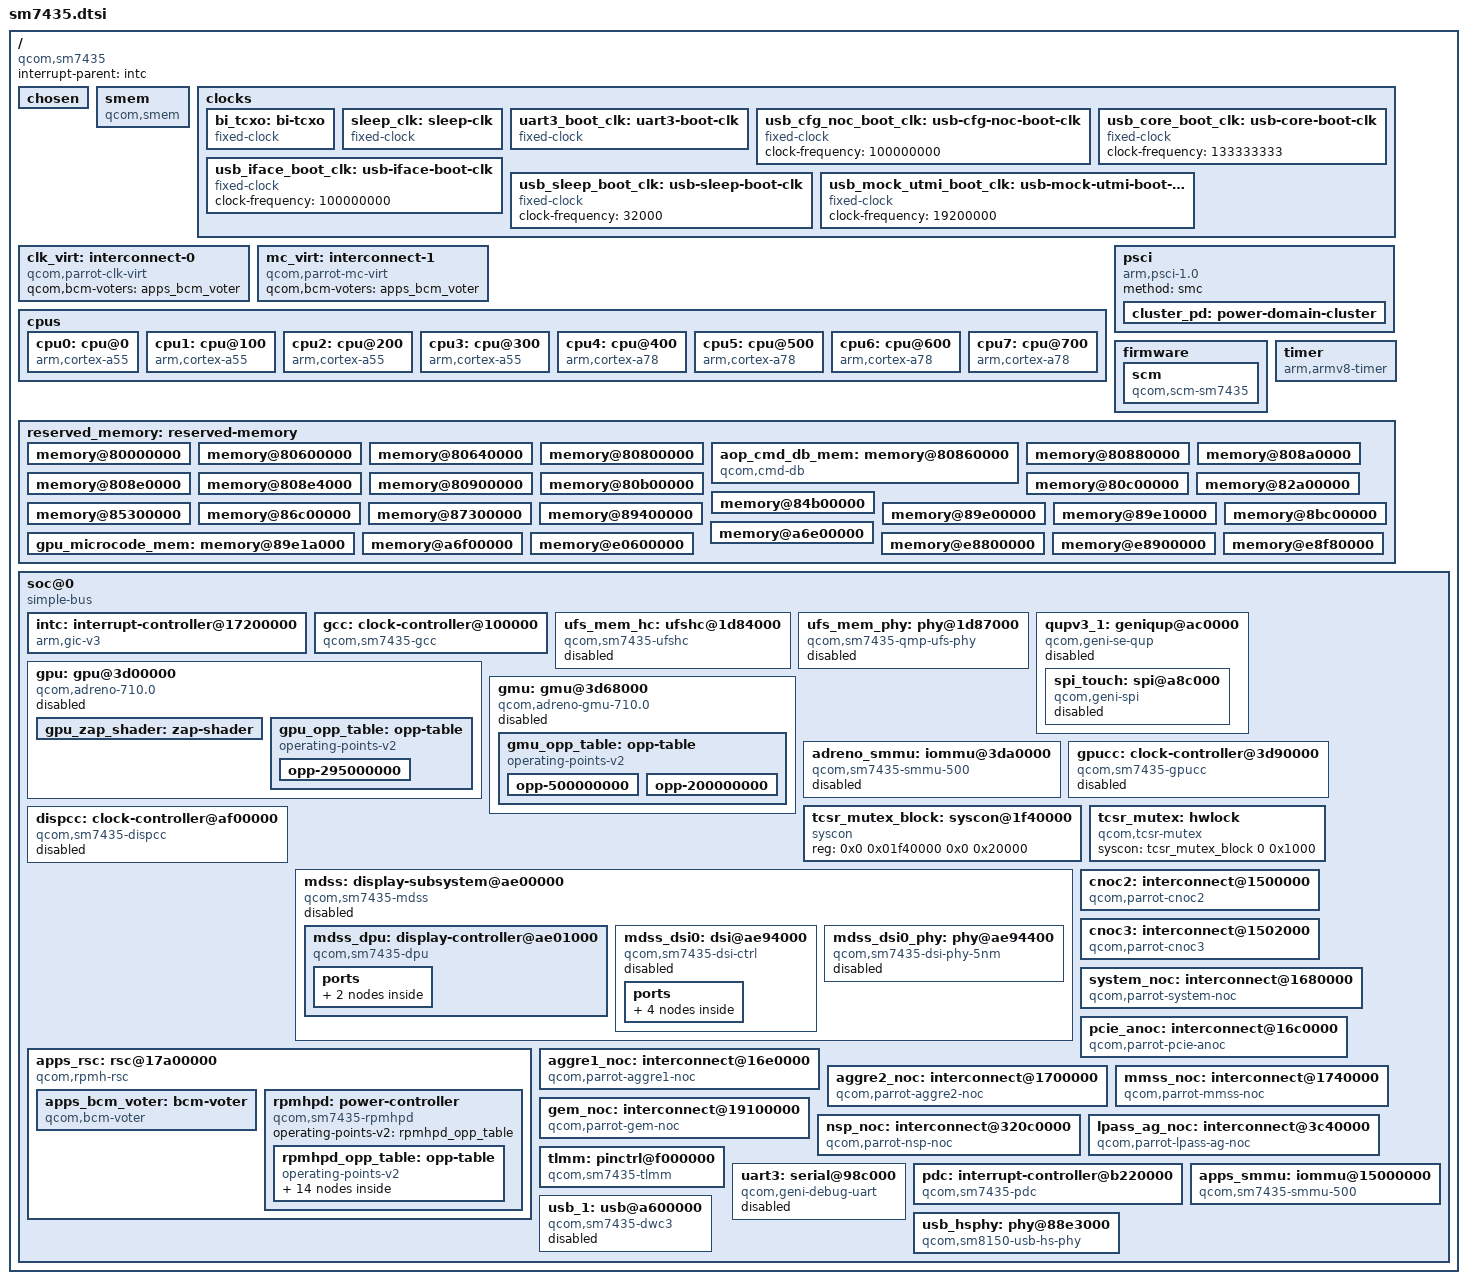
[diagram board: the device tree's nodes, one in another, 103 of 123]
// SPDX-License-Identifier: BSD-3-Clause
/*
 * Copyright (c) 2026 portov mainline contributors
 */

#include <dt-bindings/clock/qcom,sm7435-gcc.h>
#include <dt-bindings/clock/qcom,sm7435-gpucc.h>
#include <dt-bindings/clock/qcom,sm7435-dispcc.h>
#include <dt-bindings/clock/qcom,dsi-phy-28nm.h>
#include <dt-bindings/interrupt-controller/arm-gic.h>
#include <dt-bindings/gpio/gpio.h>
#include <dt-bindings/interconnect/qcom,parrot.h>
#include <dt-bindings/power/qcom,rpmhpd.h>
#include <dt-bindings/power/qcom-rpmpd.h>
#include <dt-bindings/soc/qcom,rpmh-rsc.h>

/ {
	compatible = "qcom,sm7435";
	interrupt-parent = <&intc>;

	#address-cells = <2>;
	#size-cells = <2>;

	chosen { };

	smem: smem {
		compatible = "qcom,smem";
		memory-region = <&smem_mem>;
		hwlocks = <&tcsr_mutex 3>;
	};

	clocks {
		bi_tcxo: bi-tcxo {
			compatible = "fixed-clock";
			#clock-cells = <0>;
			clock-frequency = <19200000>;
			clock-output-names = "bi_tcxo";
		};

		sleep_clk: sleep-clk {
			compatible = "fixed-clock";
			#clock-cells = <0>;
			clock-frequency = <32000>;
			clock-output-names = "sleep_clk";
		};

		uart3_boot_clk: uart3-boot-clk {
			compatible = "fixed-clock";
			#clock-cells = <0>;
			clock-frequency = <7372800>;
			clock-output-names = "qup0-se3-boot";
		};

		usb_cfg_noc_boot_clk: usb-cfg-noc-boot-clk {
			compatible = "fixed-clock";
			#clock-cells = <0>;
			clock-frequency = <100000000>;
		};

		usb_core_boot_clk: usb-core-boot-clk {
			compatible = "fixed-clock";
			#clock-cells = <0>;
			clock-frequency = <133333333>;
		};

		usb_iface_boot_clk: usb-iface-boot-clk {
			compatible = "fixed-clock";
			#clock-cells = <0>;
			clock-frequency = <100000000>;
		};

		usb_sleep_boot_clk: usb-sleep-boot-clk {
			compatible = "fixed-clock";
			#clock-cells = <0>;
			clock-frequency = <32000>;
		};

		usb_mock_utmi_boot_clk: usb-mock-utmi-boot-clk {
			compatible = "fixed-clock";
			#clock-cells = <0>;
			clock-frequency = <19200000>;
		};
	};

	clk_virt: interconnect-0 {
		compatible = "qcom,parrot-clk-virt";
		#interconnect-cells = <1>;
		qcom,bcm-voters = <&apps_bcm_voter>;
	};

	mc_virt: interconnect-1 {
		compatible = "qcom,parrot-mc-virt";
		#interconnect-cells = <1>;
		qcom,bcm-voters = <&apps_bcm_voter>;
	};

	cpus {
		#address-cells = <2>;
		#size-cells = <0>;

		cpu0: cpu@0 {
			compatible = "arm,cortex-a55";
			device_type = "cpu";
			enable-method = "psci";
			reg = <0x0 0x0>;
		};

		cpu1: cpu@100 {
			compatible = "arm,cortex-a55";
			device_type = "cpu";
			enable-method = "psci";
			reg = <0x0 0x100>;
		};

		cpu2: cpu@200 {
			compatible = "arm,cortex-a55";
			device_type = "cpu";
			enable-method = "psci";
			reg = <0x0 0x200>;
		};

		cpu3: cpu@300 {
			compatible = "arm,cortex-a55";
			device_type = "cpu";
			enable-method = "psci";
			reg = <0x0 0x300>;
		};

		cpu4: cpu@400 {
			compatible = "arm,cortex-a78";
			device_type = "cpu";
			enable-method = "psci";
			reg = <0x0 0x400>;
		};

		cpu5: cpu@500 {
			compatible = "arm,cortex-a78";
			device_type = "cpu";
			enable-method = "psci";
			reg = <0x0 0x500>;
		};

		cpu6: cpu@600 {
			compatible = "arm,cortex-a78";
			device_type = "cpu";
			enable-method = "psci";
			reg = <0x0 0x600>;
		};

		cpu7: cpu@700 {
			compatible = "arm,cortex-a78";
			device_type = "cpu";
			enable-method = "psci";
			reg = <0x0 0x700>;
		};
	};

	psci {
		compatible = "arm,psci-1.0";
		method = "smc";

		cluster_pd: power-domain-cluster {
			#power-domain-cells = <0>;
		};
	};

	firmware {
		scm: scm {
			compatible = "qcom,scm-sm7435", "qcom,scm";
		};
	};

	timer {
		compatible = "arm,armv8-timer";
		interrupts = <GIC_PPI 13 (GIC_CPU_MASK_SIMPLE(8) | IRQ_TYPE_LEVEL_LOW)>,
			     <GIC_PPI 14 (GIC_CPU_MASK_SIMPLE(8) | IRQ_TYPE_LEVEL_LOW)>,
			     <GIC_PPI 11 (GIC_CPU_MASK_SIMPLE(8) | IRQ_TYPE_LEVEL_LOW)>,
			     <GIC_PPI 12 (GIC_CPU_MASK_SIMPLE(8) | IRQ_TYPE_LEVEL_LOW)>;
		clock-frequency = <19200000>;
	};

	reserved_memory: reserved-memory {
		#address-cells = <2>;
		#size-cells = <2>;
		ranges;

		memory@80000000 {
			reg = <0x0 0x80000000 0x0 0x600000>;
			no-map;
		};

		memory@80600000 {
			reg = <0x0 0x80600000 0x0 0x40000>;
			no-map;
		};

		memory@80640000 {
			reg = <0x0 0x80640000 0x0 0x1c0000>;
			no-map;
		};

		memory@80800000 {
			reg = <0x0 0x80800000 0x0 0x60000>;
			no-map;
		};

		aop_cmd_db_mem: memory@80860000 {
			compatible = "qcom,cmd-db";
			reg = <0x0 0x80860000 0x0 0x20000>;
			no-map;
		};

		memory@80880000 {
			reg = <0x0 0x80880000 0x0 0x20000>;
			no-map;
		};

		memory@808a0000 {
			reg = <0x0 0x808a0000 0x0 0x40000>;
			no-map;
		};

		memory@808e0000 {
			reg = <0x0 0x808e0000 0x0 0x4000>;
			no-map;
		};

		memory@808e4000 {
			reg = <0x0 0x808e4000 0x0 0x10000>;
			no-map;
		};

		memory@80900000 {
			reg = <0x0 0x80900000 0x0 0x200000>;
			no-map;
		};

		memory@80b00000 {
			reg = <0x0 0x80b00000 0x0 0x100000>;
			no-map;
		};

		memory@80c00000 {
			reg = <0x0 0x80c00000 0x0 0x1000>;
			no-map;
		};

		memory@82a00000 {
			reg = <0x0 0x82a00000 0x0 0xc00000>;
			no-map;
		};

		memory@84b00000 {
			reg = <0x0 0x84b00000 0x0 0x800000>;
			no-map;
		};

		memory@85300000 {
			reg = <0x0 0x85300000 0x0 0x1900000>;
			no-map;
		};

		memory@86c00000 {
			reg = <0x0 0x86c00000 0x0 0x700000>;
			no-map;
		};

		memory@87300000 {
			reg = <0x0 0x87300000 0x0 0x2100000>;
			no-map;
		};

		memory@89400000 {
			reg = <0x0 0x89400000 0x0 0xa00000>;
			no-map;
		};

		memory@89e00000 {
			reg = <0x0 0x89e00000 0x0 0x10000>;
			no-map;
		};

		memory@89e10000 {
			reg = <0x0 0x89e10000 0x0 0xa000>;
			no-map;
		};

		gpu_microcode_mem: memory@89e1a000 {
			reg = <0x0 0x89e1a000 0x0 0x2000>;
			no-map;
		};

		memory@8bc00000 {
			reg = <0x0 0x8bc00000 0x0 0xe600000>;
			no-map;
		};

		memory@a6e00000 {
			reg = <0x0 0xa6e00000 0x0 0x40000>;
			no-map;
		};

		memory@a6f00000 {
			reg = <0x0 0xa6f00000 0x0 0x100000>;
			no-map;
		};

		memory@e0600000 {
			reg = <0x0 0xe0600000 0x0 0x400000>;
			no-map;
		};

		memory@e8800000 {
			reg = <0x0 0xe8800000 0x0 0x100000>;
			no-map;
		};

		memory@e8900000 {
			reg = <0x0 0xe8900000 0x0 0x680000>;
			no-map;
		};

		memory@e8f80000 {
			reg = <0x0 0xe8f80000 0x0 0x500000>;
			no-map;
		};
	};

	soc@0 {
		compatible = "simple-bus";
		#address-cells = <2>;
		#size-cells = <2>;
		ranges;

		intc: interrupt-controller@17200000 {
			compatible = "arm,gic-v3";
			#interrupt-cells = <3>;
			#redistributor-regions = <1>;
			interrupt-controller;
			redistributor-stride = <0x0 0x20000>;
			reg = <0x0 0x17200000 0x0 0x10000>,
			      <0x0 0x17260000 0x0 0x100000>;
			interrupts = <GIC_PPI 9 IRQ_TYPE_LEVEL_LOW>;
		};

		gcc: clock-controller@100000 {
			compatible = "qcom,sm7435-gcc";
			reg = <0x0 0x00100000 0x0 0x1f4200>;
			#clock-cells = <1>;
			#reset-cells = <1>;
			#power-domain-cells = <1>;
			clocks = <&bi_tcxo>,
				 <&sleep_clk>,
				 <0>,
				 <&ufs_mem_phy 0>,
				 <&ufs_mem_phy 1>,
				 <&ufs_mem_phy 2>,
				 <0>;
			clock-names = "bi_tcxo", "sleep_clk",
				      "pcie_0_pipe_clk",
				      "ufs_phy_rx_symbol_0_clk",
				      "ufs_phy_rx_symbol_1_clk",
				      "ufs_phy_tx_symbol_0_clk",
				      "usb3_phy_wrapper_gcc_usb30_pipe_clk";
		};

		ufs_mem_hc: ufshc@1d84000 {
			compatible = "qcom,sm7435-ufshc", "qcom,ufshc", "jedec,ufs-2.0";
			reg = <0 0x01d84000 0 0x3000>;
			interrupts = <GIC_SPI 265 IRQ_TYPE_LEVEL_HIGH>;
			phys = <&ufs_mem_phy>;
			phy-names = "ufsphy";
			lanes-per-direction = <2>;
			#reset-cells = <1>;
			resets = <&gcc GCC_UFS_PHY_BCR>;
			reset-names = "rst";
			power-domains = <&gcc GCC_UFS_PHY_GDSC>;
			iommus = <&apps_smmu 0x20 0>;
			dma-coherent;
			interconnects = <&aggre1_noc MASTER_UFS_MEM &mc_virt SLAVE_EBI1>,
				       <&gem_noc MASTER_APPSS_PROC &cnoc2 SLAVE_UFS_MEM_CFG>;
			interconnect-names = "ufs-ddr", "cpu-ufs";
			clock-names = "core_clk", "bus_aggr_clk", "iface_clk",
				      "core_clk_unipro", "ref_clk", "tx_lane0_sync_clk",
				      "rx_lane0_sync_clk", "rx_lane1_sync_clk";
			clocks = <&gcc GCC_UFS_PHY_AXI_CLK>, <&gcc GCC_AGGRE_UFS_PHY_AXI_CLK>,
				 <&gcc GCC_UFS_PHY_AHB_CLK>, <&gcc GCC_UFS_PHY_UNIPRO_CORE_CLK>,
				 <&bi_tcxo>, <&gcc GCC_UFS_PHY_TX_SYMBOL_0_CLK>,
				 <&gcc GCC_UFS_PHY_RX_SYMBOL_0_CLK>, <&gcc GCC_UFS_PHY_RX_SYMBOL_1_CLK>;
			freq-table-hz = <75000000 300000000>, <0 0>, <0 0>,
					<75000000 300000000>, <0 0>, <0 0>, <0 0>, <0 0>;
			limit-hs-gear = <3>;
			status = "disabled";
		};

		ufs_mem_phy: phy@1d87000 {
			compatible = "qcom,sm7435-qmp-ufs-phy";
			reg = <0 0x01d87000 0 0x1000>;
			clocks = <&bi_tcxo>, <&gcc GCC_UFS_PHY_PHY_AUX_CLK>,
				 <&gcc GCC_UFS_0_CLKREF_EN>;
			clock-names = "ref", "ref_aux", "qref";
			resets = <&ufs_mem_hc 0>;
			reset-names = "ufsphy";
			#clock-cells = <1>;
			#phy-cells = <0>;
			status = "disabled";
		};

		qupv3_1: geniqup@ac0000 {
			compatible = "qcom,geni-se-qup";
			reg = <0 0x00ac0000 0 0x2000>;
			#address-cells = <2>;
			#size-cells = <2>;
			ranges;
			clocks = <&gcc GCC_QUPV3_WRAP_1_M_AHB_CLK>,
				 <&gcc GCC_QUPV3_WRAP_1_S_AHB_CLK>;
			clock-names = "m-ahb", "s-ahb";
			status = "disabled";

			spi_touch: spi@a8c000 {
				compatible = "qcom,geni-spi";
				reg = <0 0x00a8c000 0 0x4000>;
				#address-cells = <1>;
				#size-cells = <0>;
				interrupts = <GIC_SPI 356 IRQ_TYPE_LEVEL_HIGH>;
				clocks = <&gcc GCC_QUPV3_WRAP1_S3_CLK>;
				clock-names = "se";
				interconnects = <&clk_virt MASTER_QUP_CORE_1 &clk_virt SLAVE_QUP_CORE_1>,
					       <&gem_noc MASTER_APPSS_PROC &cnoc2 SLAVE_QUP_1>,
					       <&aggre2_noc MASTER_QUP_1 &mc_virt SLAVE_EBI1>;
				interconnect-names = "qup-core", "qup-config", "qup-memory";
				status = "disabled";
			};
		};

		gpu: gpu@3d00000 {
			compatible = "qcom,adreno-710.0", "qcom,adreno";
			reg = <0 0x03d00000 0 0x40000>,
			      <0 0x03d9e000 0 0x1000>,
			      <0 0x03d61000 0 0x800>;
			reg-names = "kgsl_3d0_reg_memory", "cx_mem", "cx_dbgc";
			interrupts = <GIC_SPI 300 IRQ_TYPE_LEVEL_HIGH>;
			/* A710 has no LPAC stream; match the portov KGSL user SID. */
			iommus = <&adreno_smmu 0 0x400>;
			qcom,gmu = <&gmu>;
			operating-points-v2 = <&gpu_opp_table>;
			interconnects = <&gem_noc MASTER_GFX3D &mc_virt SLAVE_EBI1>;
			interconnect-names = "gfx-mem";
			status = "disabled";

			gpu_zap_shader: zap-shader {
				memory-region = <&gpu_microcode_mem>;
				firmware-name = "qcom/a710_zap.mdt";
			};

			gpu_opp_table: opp-table {
				compatible = "operating-points-v2";
				opp-295000000 {
					opp-hz = /bits/ 64 <295000000>;
					opp-level = <RPMH_REGULATOR_LEVEL_LOW_SVS_D1>;
					opp-peak-kBps = <800000>;
				};
			};
		};

		gmu: gmu@3d68000 {
			compatible = "qcom,adreno-gmu-710.0", "qcom,adreno-gmu";
			reg = <0 0x03d68000 0 0x37000>,
			      <0 0x03d50000 0 0x10000>,
			      <0 0x0b270000 0 0x10000>;
			reg-names = "gmu", "rscc", "gmu_pdc";
			interrupts = <GIC_SPI 304 IRQ_TYPE_LEVEL_HIGH>,
				     <GIC_SPI 305 IRQ_TYPE_LEVEL_HIGH>;
			interrupt-names = "hfi", "gmu";
			clocks = <&gpucc GPU_CC_AHB_CLK>, <&gpucc GPU_CC_CX_GMU_CLK>,
				 <&gpucc GPU_CC_CXO_CLK>, <&gcc GCC_DDRSS_GPU_AXI_CLK>,
				 <&gcc GCC_GPU_MEMNOC_GFX_CLK>,
				 <&gpucc GPU_CC_HUB_CX_INT_CLK>, <&gpucc GPU_CC_DEMET_CLK>;
			clock-names = "ahb", "gmu", "cxo", "axi", "memnoc", "hub", "demet";
			power-domains = <&gpucc GPU_CC_CX_GDSC>, <&gpucc GPU_CC_GX_GDSC>;
			power-domain-names = "cx", "gx";
			iommus = <&adreno_smmu 5 0x400>;
			operating-points-v2 = <&gmu_opp_table>;
			status = "disabled";

			gmu_opp_table: opp-table {
				compatible = "operating-points-v2";
				opp-500000000 {
					opp-hz = /bits/ 64 <500000000>;
					opp-level = <RPMH_REGULATOR_LEVEL_SVS>;
				};
				opp-200000000 {
					opp-hz = /bits/ 64 <200000000>;
					opp-level = <RPMH_REGULATOR_LEVEL_LOW_SVS>;
				};
			};
		};

		adreno_smmu: iommu@3da0000 {
			compatible = "qcom,sm7435-smmu-500", "qcom,adreno-smmu",
				     "qcom,smmu-500", "arm,mmu-500";
			reg = <0 0x03da0000 0 0x40000>;
			#iommu-cells = <2>;
			#global-interrupts = <1>;
			interrupts = <GIC_SPI 673 IRQ_TYPE_LEVEL_HIGH>,
			             <GIC_SPI 678 IRQ_TYPE_LEVEL_HIGH>,
			             <GIC_SPI 679 IRQ_TYPE_LEVEL_HIGH>,
			             <GIC_SPI 680 IRQ_TYPE_LEVEL_HIGH>,
			             <GIC_SPI 681 IRQ_TYPE_LEVEL_HIGH>,
			             <GIC_SPI 682 IRQ_TYPE_LEVEL_HIGH>,
			             <GIC_SPI 683 IRQ_TYPE_LEVEL_HIGH>,
			             <GIC_SPI 684 IRQ_TYPE_LEVEL_HIGH>,
			             <GIC_SPI 685 IRQ_TYPE_LEVEL_HIGH>,
			             <GIC_SPI 686 IRQ_TYPE_LEVEL_HIGH>,
			             <GIC_SPI 687 IRQ_TYPE_LEVEL_HIGH>,
			             <GIC_SPI 422 IRQ_TYPE_LEVEL_HIGH>,
			             <GIC_SPI 476 IRQ_TYPE_LEVEL_HIGH>,
			             <GIC_SPI 574 IRQ_TYPE_LEVEL_HIGH>,
			             <GIC_SPI 575 IRQ_TYPE_LEVEL_HIGH>,
			             <GIC_SPI 576 IRQ_TYPE_LEVEL_HIGH>,
			             <GIC_SPI 577 IRQ_TYPE_LEVEL_HIGH>,
			             <GIC_SPI 659 IRQ_TYPE_LEVEL_HIGH>,
			             <GIC_SPI 661 IRQ_TYPE_LEVEL_HIGH>,
			             <GIC_SPI 664 IRQ_TYPE_LEVEL_HIGH>,
			             <GIC_SPI 665 IRQ_TYPE_LEVEL_HIGH>,
			             <GIC_SPI 666 IRQ_TYPE_LEVEL_HIGH>,
			             <GIC_SPI 668 IRQ_TYPE_LEVEL_HIGH>,
			             <GIC_SPI 669 IRQ_TYPE_LEVEL_HIGH>,
			             <GIC_SPI 699 IRQ_TYPE_LEVEL_HIGH>,
			             <GIC_SPI 700 IRQ_TYPE_LEVEL_HIGH>;
			clocks = <&gpucc GPU_CC_CX_GMU_CLK>,
				 <&gpucc GPU_CC_HUB_CX_INT_CLK>,
				 <&gpucc GPU_CC_HLOS1_VOTE_GPU_SMMU_CLK>,
				 <&gcc GCC_GPU_MEMNOC_GFX_CLK>,
				 <&gcc GCC_GPU_SNOC_DVM_GFX_CLK>, <&gpucc GPU_CC_AHB_CLK>;
			clock-names = "gmu", "hub", "hlos", "bus", "iface", "ahb";
			power-domains = <&gpucc GPU_CC_CX_GDSC>;
			dma-coherent;
			status = "disabled";
		};

		gpucc: clock-controller@3d90000 {
			compatible = "qcom,sm7435-gpucc";
			reg = <0 0x03d90000 0 0xa000>;
			clocks = <&bi_tcxo>, <&gcc GCC_GPU_GPLL0_CLK_SRC>,
				 <&gcc GCC_GPU_GPLL0_DIV_CLK_SRC>,
				 <&gcc GCC_GPU_SNOC_DVM_GFX_CLK>;
			clock-names = "bi_tcxo", "gpll0_out_main",
				      "gpll0_out_main_div", "gcc_gpu_snoc_dvm_gfx_clk";
			power-domains = <&rpmhpd RPMHPD_MX>, <&rpmhpd RPMHPD_CX>;
			power-domain-names = "mx", "cx";
			required-opps = <&rpmhpd_opp_svs>, <&rpmhpd_opp_svs>;
			#clock-cells = <1>;
			#reset-cells = <1>;
			#power-domain-cells = <1>;
			status = "disabled";
		};

		tcsr_mutex_block: syscon@1f40000 {
			compatible = "syscon";
			reg = <0x0 0x01f40000 0x0 0x20000>;
		};

		tcsr_mutex: hwlock {
			compatible = "qcom,tcsr-mutex";
			syscon = <&tcsr_mutex_block 0 0x1000>;
			#hwlock-cells = <1>;
		};

		dispcc: clock-controller@af00000 {
			compatible = "qcom,sm7435-dispcc";
			reg = <0x0 0x0af00000 0x0 0x20000>;
			clocks = <&bi_tcxo>,
				 <&bi_tcxo>,
				 <&gcc GCC_DISP_AHB_CLK>,
				 <&sleep_clk>,
				 <&mdss_dsi0_phy DSI_BYTE_PLL_CLK>,
				 <&mdss_dsi0_phy DSI_PIXEL_PLL_CLK>;
			#clock-cells = <1>;
			#reset-cells = <1>;
			status = "disabled";
		};

		mdss: display-subsystem@ae00000 {
			compatible = "qcom,sm7435-mdss";
			reg = <0x0 0x0ae00000 0x0 0x1000>;
			reg-names = "mdss";
			interrupts = <GIC_SPI 83 IRQ_TYPE_LEVEL_HIGH>;
			interrupt-controller;
			#interrupt-cells = <1>;
			#address-cells = <2>;
			#size-cells = <2>;
			ranges;
			clocks = <&dispcc DISP_CC_MDSS_AHB_CLK>,
				 <&gcc GCC_DISP_HF_AXI_CLK>,
				 <&dispcc DISP_CC_MDSS_MDP_CLK>;
			clock-names = "iface", "bus", "core";
			interconnects = <&mmss_noc MASTER_MDP_DISP
					 &mc_virt SLAVE_EBI1_DISP>,
					<&mmss_noc MASTER_MDP_DISP
					 &mc_virt SLAVE_EBI1_DISP>,
					<&gem_noc MASTER_APPSS_PROC
					 &cnoc2 SLAVE_DISPLAY_CFG>;
			interconnect-names = "mdp0-mem", "mdp1-mem", "cpu-cfg";
			power-domains = <&rpmhpd RPMHPD_CX>;
			status = "disabled";

			mdss_dpu: display-controller@ae01000 {
				compatible = "qcom,sm7435-dpu";
				reg = <0x0 0x0ae01000 0x0 0x8f000>,
				      <0x0 0x0aeb0000 0x0 0x3000>;
				reg-names = "mdp", "vbif";
				interrupt-parent = <&mdss>;
				interrupts = <0>;
				clocks = <&gcc GCC_DISP_HF_AXI_CLK>,
					 <&dispcc DISP_CC_MDSS_AHB_CLK>,
					 <&dispcc DISP_CC_MDSS_MDP_LUT_CLK>,
					 <&dispcc DISP_CC_MDSS_MDP_CLK>,
					 <&dispcc DISP_CC_MDSS_VSYNC_CLK>;
				clock-names = "bus", "iface", "lut", "core", "vsync";
				portov,iommus = <&apps_smmu 0x800 0x402>;
				ports {
					#address-cells = <1>;
					#size-cells = <0>;

					port@0 {
						reg = <0>;
						mdss_dpu_out: endpoint {
							remote-endpoint = <&mdss_dsi0_in>;
						};
					};
				};
			};

			mdss_dsi0: dsi@ae94000 {
				compatible = "qcom,sm7435-dsi-ctrl", "qcom,mdss-dsi-ctrl";
				reg = <0x0 0x0ae94000 0x0 0x400>;
				reg-names = "dsi_ctrl";
				interrupt-parent = <&mdss>;
				interrupts = <4>;
				clocks = <&dispcc DISP_CC_MDSS_BYTE0_CLK>,
					 <&dispcc DISP_CC_MDSS_BYTE0_INTF_CLK>,
					 <&dispcc DISP_CC_MDSS_PCLK0_CLK>,
					 <&dispcc DISP_CC_MDSS_ESC0_CLK>,
					 <&dispcc DISP_CC_MDSS_AHB_CLK>,
					 <&gcc GCC_DISP_HF_AXI_CLK>;
				clock-names = "byte", "byte_intf", "pixel", "core",
					      "iface", "bus";
				assigned-clocks = <&dispcc DISP_CC_MDSS_BYTE0_CLK_SRC>,
						  <&dispcc DISP_CC_MDSS_PCLK0_CLK_SRC>;
				assigned-clock-parents = <&mdss_dsi0_phy DSI_BYTE_PLL_CLK>,
							 <&mdss_dsi0_phy DSI_PIXEL_PLL_CLK>;
				phys = <&mdss_dsi0_phy>;
				phy-names = "dsi";
				#address-cells = <1>;
				#size-cells = <0>;
				status = "disabled";

				ports {
					#address-cells = <1>;
					#size-cells = <0>;

					port@0 {
						reg = <0>;
						mdss_dsi0_in: endpoint {
							remote-endpoint = <&mdss_dpu_out>;
						};
					};

					port@1 {
						reg = <1>;
						mdss_dsi0_out: endpoint {
						};
					};
				};
			};

			mdss_dsi0_phy: phy@ae94400 {
				compatible = "qcom,sm7435-dsi-phy-5nm";
				reg = <0x0 0x0ae94400 0x0 0x200>,
				      <0x0 0x0ae94600 0x0 0x280>,
				      <0x0 0x0ae94900 0x0 0x260>;
				reg-names = "dsi_phy", "dsi_phy_lane", "dsi_pll";
				#clock-cells = <1>;
				#phy-cells = <0>;
				clocks = <&dispcc DISP_CC_MDSS_AHB_CLK>,
					 <&bi_tcxo>;
				clock-names = "iface", "ref";
				status = "disabled";
			};
		};

		apps_rsc: rsc@17a00000 {
			compatible = "qcom,rpmh-rsc";
			reg = <0x0 0x17a00000 0x0 0x10000>,
			      <0x0 0x17a10000 0x0 0x10000>,
			      <0x0 0x17a20000 0x0 0x10000>;
			reg-names = "drv-0", "drv-1", "drv-2";
			interrupts = <GIC_SPI 3 IRQ_TYPE_LEVEL_HIGH>,
				     <GIC_SPI 4 IRQ_TYPE_LEVEL_HIGH>,
				     <GIC_SPI 5 IRQ_TYPE_LEVEL_HIGH>;
			power-domains = <&cluster_pd>;
			qcom,tcs-offset = <0xd00>;
			qcom,drv-id = <2>;
			qcom,tcs-config = <ACTIVE_TCS 3>, <SLEEP_TCS 2>,
					  <WAKE_TCS 2>, <CONTROL_TCS 0>;
			label = "apps_rsc";

			apps_bcm_voter: bcm-voter {
				compatible = "qcom,bcm-voter";
			};

			rpmhpd: power-controller {
				compatible = "qcom,sm7435-rpmhpd";
				#power-domain-cells = <1>;
				operating-points-v2 = <&rpmhpd_opp_table>;

				rpmhpd_opp_table: opp-table {
					compatible = "operating-points-v2";

					rpmhpd_opp_ret: opp-16 {
						opp-level = <RPMH_REGULATOR_LEVEL_RETENTION>;
					};

					rpmhpd_opp_min_svs: opp-48 {
						opp-level = <RPMH_REGULATOR_LEVEL_MIN_SVS>;
					};

					rpmhpd_opp_low_svs_d1: opp-56 {
						opp-level = <RPMH_REGULATOR_LEVEL_LOW_SVS_D1>;
					};

					rpmhpd_opp_low_svs: opp-64 {
						opp-level = <RPMH_REGULATOR_LEVEL_LOW_SVS>;
					};

					rpmhpd_opp_low_svs_l1: opp-80 {
						opp-level = <RPMH_REGULATOR_LEVEL_LOW_SVS_L1>;
					};

					rpmhpd_opp_low_svs_l2: opp-96 {
						opp-level = <RPMH_REGULATOR_LEVEL_LOW_SVS_L2>;
					};

					rpmhpd_opp_svs: opp-128 {
						opp-level = <RPMH_REGULATOR_LEVEL_SVS>;
					};

					rpmhpd_opp_svs_l1: opp-192 {
						opp-level = <RPMH_REGULATOR_LEVEL_SVS_L1>;
					};

					rpmhpd_opp_svs_l2: opp-224 {
						opp-level = <RPMH_REGULATOR_LEVEL_SVS_L2>;
					};

					rpmhpd_opp_nom: opp-256 {
						opp-level = <RPMH_REGULATOR_LEVEL_NOM>;
					};

					rpmhpd_opp_nom_l1: opp-320 {
						opp-level = <RPMH_REGULATOR_LEVEL_NOM_L1>;
					};

					rpmhpd_opp_nom_l2: opp-336 {
						opp-level = <RPMH_REGULATOR_LEVEL_NOM_L2>;
					};

					rpmhpd_opp_turbo: opp-384 {
						opp-level = <RPMH_REGULATOR_LEVEL_TURBO>;
					};

					rpmhpd_opp_turbo_l1: opp-416 {
						opp-level = <RPMH_REGULATOR_LEVEL_TURBO_L1>;
					};
				};
			};
		};

		cnoc2: interconnect@1500000 {
			compatible = "qcom,parrot-cnoc2";
			reg = <0x0 0x01500000 0x0 0x1000>;
			#interconnect-cells = <1>;
			qcom,bcm-voters = <&apps_bcm_voter>;
		};

		cnoc3: interconnect@1502000 {
			compatible = "qcom,parrot-cnoc3";
			reg = <0x0 0x01502000 0x0 0x1000>;
			#interconnect-cells = <1>;
			qcom,bcm-voters = <&apps_bcm_voter>;
		};

		system_noc: interconnect@1680000 {
			compatible = "qcom,parrot-system-noc";
			reg = <0x0 0x01680000 0x0 0x1e200>;
			#interconnect-cells = <1>;
			qcom,bcm-voters = <&apps_bcm_voter>;
		};

		pcie_anoc: interconnect@16c0000 {
			compatible = "qcom,parrot-pcie-anoc";
			reg = <0x0 0x016c0000 0x0 0xe280>;
			#interconnect-cells = <1>;
			clocks = <&gcc GCC_AGGRE_NOC_PCIE_0_AXI_CLK>,
				 <&gcc GCC_CFG_NOC_PCIE_ANOC_AHB_CLK>;
			qcom,bcm-voters = <&apps_bcm_voter>;
		};

		aggre1_noc: interconnect@16e0000 {
			compatible = "qcom,parrot-aggre1-noc";
			reg = <0x0 0x016e0000 0x0 0x1c080>;
			#interconnect-cells = <1>;
			clocks = <&gcc GCC_AGGRE_USB3_PRIM_AXI_CLK>;
			qcom,bcm-voters = <&apps_bcm_voter>;
		};

		aggre2_noc: interconnect@1700000 {
			compatible = "qcom,parrot-aggre2-noc";
			reg = <0x0 0x01700000 0x0 0x31080>;
			#interconnect-cells = <1>;
			clocks = <&gcc GCC_SDCC2_AHB_CLK>;
			qcom,bcm-voters = <&apps_bcm_voter>;
		};

		mmss_noc: interconnect@1740000 {
			compatible = "qcom,parrot-mmss-noc";
			reg = <0x0 0x01740000 0x0 0x1f080>;
			#interconnect-cells = <1>;
			qcom,bcm-voters = <&apps_bcm_voter>;
		};

		gem_noc: interconnect@19100000 {
			compatible = "qcom,parrot-gem-noc";
			reg = <0x0 0x19100000 0x0 0xbb800>;
			#interconnect-cells = <1>;
			qcom,bcm-voters = <&apps_bcm_voter>;
		};

		nsp_noc: interconnect@320c0000 {
			compatible = "qcom,parrot-nsp-noc";
			reg = <0x0 0x320c0000 0x0 0x10000>;
			#interconnect-cells = <1>;
			qcom,bcm-voters = <&apps_bcm_voter>;
		};

		lpass_ag_noc: interconnect@3c40000 {
			compatible = "qcom,parrot-lpass-ag-noc";
			reg = <0x0 0x03c40000 0x0 0x17200>;
			#interconnect-cells = <1>;
			qcom,bcm-voters = <&apps_bcm_voter>;
		};

		tlmm: pinctrl@f000000 {
			compatible = "qcom,sm7435-tlmm";
			reg = <0x0 0x0f000000 0x0 0x1000000>;
			interrupts = <GIC_SPI 208 IRQ_TYPE_LEVEL_HIGH>;
			gpio-controller;
			#gpio-cells = <2>;
			interrupt-controller;
			#interrupt-cells = <2>;
			gpio-reserved-ranges = <0 4>, <18 4>, <38 1>;
			gpio-ranges = <&tlmm 0 0 142>;
			wakeup-parent = <&pdc>;
		};

		uart3: serial@98c000 {
			compatible = "qcom,geni-debug-uart";
			reg = <0x0 0x0098c000 0x0 0x4000>;
			clocks = <&uart3_boot_clk>;
			clock-names = "se";
			interrupts = <GIC_SPI 604 IRQ_TYPE_LEVEL_HIGH>;
			status = "disabled";
		};

		pdc: interrupt-controller@b220000 {
			compatible = "qcom,sm7435-pdc", "qcom,pdc";
			reg = <0x0 0x0b220000 0x0 0x30000>,
			      <0x0 0x174000f0 0x0 0x64>;
			qcom,pdc-ranges = <0 480 94>, <94 609 31>,
					  <125 63 1>, <126 716 12>;
			#interrupt-cells = <2>;
			interrupt-parent = <&intc>;
			interrupt-controller;
		};

		apps_smmu: iommu@15000000 {
			compatible = "qcom,sm7435-smmu-500", "qcom,smmu-500", "arm,mmu-500";
			reg = <0x0 0x15000000 0x0 0x100000>;
			#iommu-cells = <2>;
			#global-interrupts = <1>;
			dma-coherent;
			qcom,skip-init;
			qcom,handoff-smrs = <0x800 0x402>;
			qcom,reclaim-smrs = <0x80 0x0>, <0x800 0x402>, <0x20 0x0>;
			qcom,num-smr-override = <120>;
			qcom,num-context-banks-override = <78>;

			interrupts = <GIC_SPI 65 IRQ_TYPE_LEVEL_HIGH>,
				     <GIC_SPI 96 IRQ_TYPE_LEVEL_HIGH>,
				     <GIC_SPI 670 IRQ_TYPE_LEVEL_HIGH>,
				     <GIC_SPI 671 IRQ_TYPE_LEVEL_HIGH>,
				     <GIC_SPI 97 IRQ_TYPE_LEVEL_HIGH>,
				     <GIC_SPI 98 IRQ_TYPE_LEVEL_HIGH>,
				     <GIC_SPI 99 IRQ_TYPE_LEVEL_HIGH>,
				     <GIC_SPI 100 IRQ_TYPE_LEVEL_HIGH>,
				     <GIC_SPI 101 IRQ_TYPE_LEVEL_HIGH>,
				     <GIC_SPI 102 IRQ_TYPE_LEVEL_HIGH>,
				     <GIC_SPI 103 IRQ_TYPE_LEVEL_HIGH>,
				     <GIC_SPI 104 IRQ_TYPE_LEVEL_HIGH>,
				     <GIC_SPI 105 IRQ_TYPE_LEVEL_HIGH>,
				     <GIC_SPI 106 IRQ_TYPE_LEVEL_HIGH>,
				     <GIC_SPI 107 IRQ_TYPE_LEVEL_HIGH>,
				     <GIC_SPI 108 IRQ_TYPE_LEVEL_HIGH>,
				     <GIC_SPI 109 IRQ_TYPE_LEVEL_HIGH>,
				     <GIC_SPI 110 IRQ_TYPE_LEVEL_HIGH>,
				     <GIC_SPI 111 IRQ_TYPE_LEVEL_HIGH>,
				     <GIC_SPI 112 IRQ_TYPE_LEVEL_HIGH>,
				     <GIC_SPI 113 IRQ_TYPE_LEVEL_HIGH>,
				     <GIC_SPI 114 IRQ_TYPE_LEVEL_HIGH>,
				     <GIC_SPI 115 IRQ_TYPE_LEVEL_HIGH>,
				     <GIC_SPI 116 IRQ_TYPE_LEVEL_HIGH>,
				     <GIC_SPI 117 IRQ_TYPE_LEVEL_HIGH>,
				     <GIC_SPI 118 IRQ_TYPE_LEVEL_HIGH>,
				     <GIC_SPI 181 IRQ_TYPE_LEVEL_HIGH>,
				     <GIC_SPI 182 IRQ_TYPE_LEVEL_HIGH>,
				     <GIC_SPI 183 IRQ_TYPE_LEVEL_HIGH>,
				     <GIC_SPI 184 IRQ_TYPE_LEVEL_HIGH>,
				     <GIC_SPI 185 IRQ_TYPE_LEVEL_HIGH>,
				     <GIC_SPI 186 IRQ_TYPE_LEVEL_HIGH>,
				     <GIC_SPI 187 IRQ_TYPE_LEVEL_HIGH>,
				     <GIC_SPI 188 IRQ_TYPE_LEVEL_HIGH>,
				     <GIC_SPI 189 IRQ_TYPE_LEVEL_HIGH>,
				     <GIC_SPI 190 IRQ_TYPE_LEVEL_HIGH>,
				     <GIC_SPI 191 IRQ_TYPE_LEVEL_HIGH>,
				     <GIC_SPI 192 IRQ_TYPE_LEVEL_HIGH>,
				     <GIC_SPI 315 IRQ_TYPE_LEVEL_HIGH>,
				     <GIC_SPI 316 IRQ_TYPE_LEVEL_HIGH>,
				     <GIC_SPI 317 IRQ_TYPE_LEVEL_HIGH>,
				     <GIC_SPI 318 IRQ_TYPE_LEVEL_HIGH>,
				     <GIC_SPI 319 IRQ_TYPE_LEVEL_HIGH>,
				     <GIC_SPI 320 IRQ_TYPE_LEVEL_HIGH>,
				     <GIC_SPI 321 IRQ_TYPE_LEVEL_HIGH>,
				     <GIC_SPI 322 IRQ_TYPE_LEVEL_HIGH>,
				     <GIC_SPI 323 IRQ_TYPE_LEVEL_HIGH>,
				     <GIC_SPI 324 IRQ_TYPE_LEVEL_HIGH>,
				     <GIC_SPI 325 IRQ_TYPE_LEVEL_HIGH>,
				     <GIC_SPI 326 IRQ_TYPE_LEVEL_HIGH>,
				     <GIC_SPI 327 IRQ_TYPE_LEVEL_HIGH>,
				     <GIC_SPI 328 IRQ_TYPE_LEVEL_HIGH>,
				     <GIC_SPI 329 IRQ_TYPE_LEVEL_HIGH>,
				     <GIC_SPI 330 IRQ_TYPE_LEVEL_HIGH>,
				     <GIC_SPI 331 IRQ_TYPE_LEVEL_HIGH>,
				     <GIC_SPI 332 IRQ_TYPE_LEVEL_HIGH>,
				     <GIC_SPI 333 IRQ_TYPE_LEVEL_HIGH>,
				     <GIC_SPI 334 IRQ_TYPE_LEVEL_HIGH>,
				     <GIC_SPI 335 IRQ_TYPE_LEVEL_HIGH>,
				     <GIC_SPI 336 IRQ_TYPE_LEVEL_HIGH>,
				     <GIC_SPI 337 IRQ_TYPE_LEVEL_HIGH>,
				     <GIC_SPI 338 IRQ_TYPE_LEVEL_HIGH>,
				     <GIC_SPI 339 IRQ_TYPE_LEVEL_HIGH>,
				     <GIC_SPI 340 IRQ_TYPE_LEVEL_HIGH>,
				     <GIC_SPI 341 IRQ_TYPE_LEVEL_HIGH>,
				     <GIC_SPI 342 IRQ_TYPE_LEVEL_HIGH>,
				     <GIC_SPI 343 IRQ_TYPE_LEVEL_HIGH>,
				     <GIC_SPI 344 IRQ_TYPE_LEVEL_HIGH>,
				     <GIC_SPI 345 IRQ_TYPE_LEVEL_HIGH>,
				     <GIC_SPI 395 IRQ_TYPE_LEVEL_HIGH>,
				     <GIC_SPI 396 IRQ_TYPE_LEVEL_HIGH>,
				     <GIC_SPI 397 IRQ_TYPE_LEVEL_HIGH>,
				     <GIC_SPI 398 IRQ_TYPE_LEVEL_HIGH>,
				     <GIC_SPI 399 IRQ_TYPE_LEVEL_HIGH>,
				     <GIC_SPI 400 IRQ_TYPE_LEVEL_HIGH>,
				     <GIC_SPI 401 IRQ_TYPE_LEVEL_HIGH>,
				     <GIC_SPI 402 IRQ_TYPE_LEVEL_HIGH>,
				     <GIC_SPI 403 IRQ_TYPE_LEVEL_HIGH>,
				     <GIC_SPI 404 IRQ_TYPE_LEVEL_HIGH>,
				     <GIC_SPI 405 IRQ_TYPE_LEVEL_HIGH>,
				     <GIC_SPI 406 IRQ_TYPE_LEVEL_HIGH>,
				     <GIC_SPI 407 IRQ_TYPE_LEVEL_HIGH>,
				     <GIC_SPI 408 IRQ_TYPE_LEVEL_HIGH>,
				     <GIC_SPI 409 IRQ_TYPE_LEVEL_HIGH>,
				     <GIC_SPI 412 IRQ_TYPE_LEVEL_HIGH>,
				     <GIC_SPI 418 IRQ_TYPE_LEVEL_HIGH>,
				     <GIC_SPI 419 IRQ_TYPE_LEVEL_HIGH>,
				     <GIC_SPI 421 IRQ_TYPE_LEVEL_HIGH>,
				     <GIC_SPI 706 IRQ_TYPE_LEVEL_HIGH>,
				     <GIC_SPI 423 IRQ_TYPE_LEVEL_HIGH>,
				     <GIC_SPI 424 IRQ_TYPE_LEVEL_HIGH>,
				     <GIC_SPI 425 IRQ_TYPE_LEVEL_HIGH>,
				     <GIC_SPI 689 IRQ_TYPE_LEVEL_HIGH>,
				     <GIC_SPI 690 IRQ_TYPE_LEVEL_HIGH>,
				     <GIC_SPI 691 IRQ_TYPE_LEVEL_HIGH>,
				     <GIC_SPI 692 IRQ_TYPE_LEVEL_HIGH>,
				     <GIC_SPI 693 IRQ_TYPE_LEVEL_HIGH>;

			status = "okay";
		};

		usb_hsphy: phy@88e3000 {
			compatible = "qcom,sm8150-usb-hs-phy", "qcom,usb-snps-hs-7nm-phy";
			reg = <0x0 0x088e3000 0x0 0x11c>;
			#phy-cells = <0>;

			clocks = <&gcc GCC_EUSB3_0_CLKREF_EN>;
			clock-names = "ref";
			resets = <&gcc GCC_QUSB2PHY_PRIM_BCR>;

			vdda-pll-supply = <&usb_hs_core>;
			vdda18-supply = <&usb_hs_1v8>;
			vdda33-supply = <&usb_hs_3v3>;
			status = "okay";
		};

		usb_1: usb@a600000 {
			compatible = "qcom,sm7435-dwc3", "qcom,snps-dwc3";
			reg = <0x0 0x0a600000 0x0 0xfc100>;

			/*
			 * Use the GCC provider for all DWC3 clocks.  Rates remain
			 * inherited from the bootloader for this first consumer switch;
			 * assigning shared RCG rates is a separate hardware-ownership
			 * step.
			 */
			clocks = <&gcc GCC_CFG_NOC_USB3_PRIM_AXI_CLK>,
				 <&gcc GCC_USB30_PRIM_MASTER_CLK>,
				 <&gcc GCC_AGGRE_USB3_PRIM_AXI_CLK>,
				 <&gcc GCC_USB30_PRIM_SLEEP_CLK>,
				 <&gcc GCC_USB30_PRIM_MOCK_UTMI_CLK>;
			clock-names = "cfg_noc", "core", "iface", "sleep",
				      "mock_utmi";
			assigned-clocks = <&gcc GCC_USB30_PRIM_MOCK_UTMI_CLK_SRC>,
					  <&gcc GCC_USB30_PRIM_MASTER_CLK_SRC>;
			assigned-clock-rates = <19200000>, <133333333>;
			resets = <&gcc GCC_USB30_PRIM_BCR>;
			power-domains = <&gcc GCC_USB30_PRIM_GDSC>;
			phys = <&usb_hsphy>;
			phy-names = "usb2-phy";
			iommus = <&apps_smmu 0x80 0>;
			/*
			 * Keep the proven non-coherent DMA behavior. The SMMU
			 * provides address translation; coherent DMA can be
			 * enabled separately after hardware validation.
			 */
			interconnects = <&aggre1_noc MASTER_USB3_0
					 &mc_virt SLAVE_EBI1>,
					<&gem_noc MASTER_APPSS_PROC
					 &cnoc2 SLAVE_USB3_0>;
			interconnect-names = "usb-ddr", "apps-usb";

			interrupts-extended = <&intc GIC_SPI 133 IRQ_TYPE_LEVEL_HIGH>,
					      <&intc GIC_SPI 130 IRQ_TYPE_LEVEL_HIGH>,
					      <&pdc 14 IRQ_TYPE_EDGE_RISING>,
					      <&pdc 15 IRQ_TYPE_EDGE_RISING>,
					      <&pdc 17 IRQ_TYPE_LEVEL_HIGH>;
			interrupt-names = "dwc_usb3", "pwr_event", "dp_hs_phy_irq",
					  "dm_hs_phy_irq", "ss_phy_irq";

			qcom,select-utmi-as-pipe-clk;
			snps,dis_u2_susphy_quirk;
			snps,dis_enblslpm_quirk;
			snps,dis-u1-entry-quirk;
			snps,dis-u2-entry-quirk;
			dr_mode = "peripheral";
			maximum-speed = "high-speed";

			status = "disabled";
		};
	};
};
